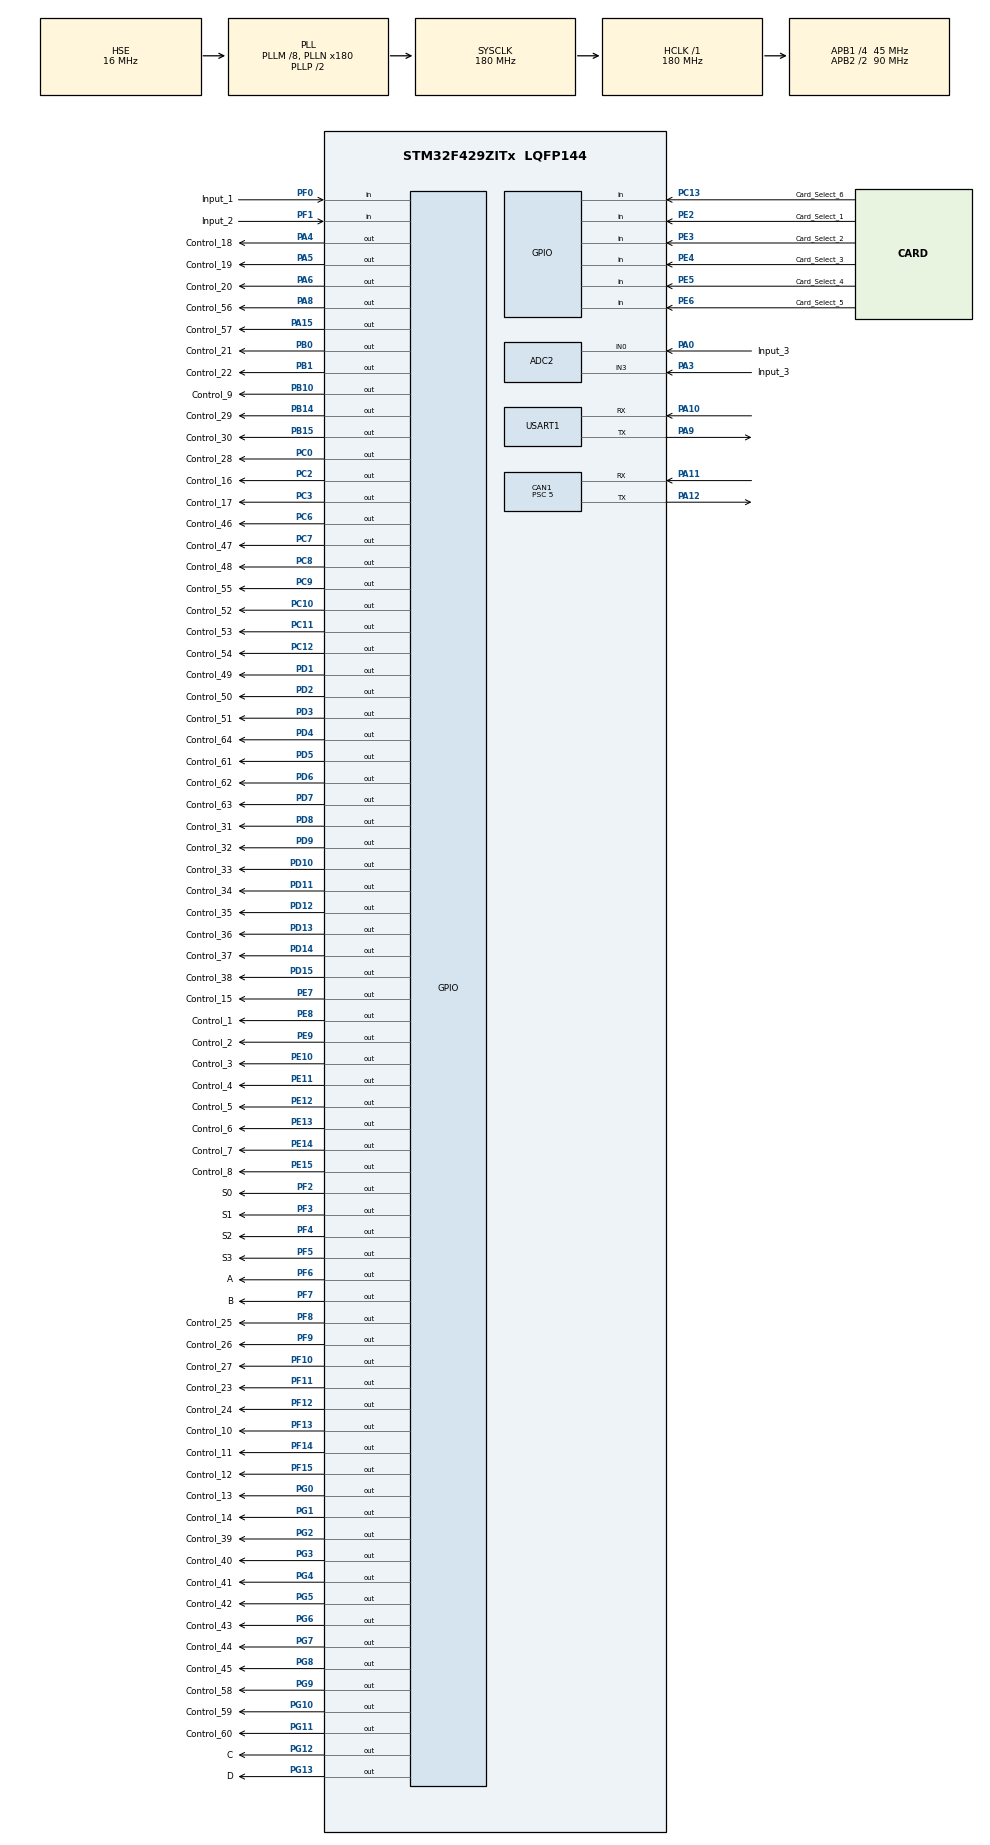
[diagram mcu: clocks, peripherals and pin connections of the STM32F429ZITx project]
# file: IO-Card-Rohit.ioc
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ADC2.Channel-0\#ChannelRegularConversion=ADC_CHANNEL_0
ADC2.Channel-1\#ChannelRegularConversion=ADC_CHANNEL_0
ADC2.ClockPrescaler=ADC_CLOCK_SYNC_PCLK_DIV4
ADC2.ContinuousConvMode=ENABLE
ADC2.NbrOfConversion=2
ADC2.NbrOfConversionFlag=1
ADC2.Rank-0\#ChannelRegularConversion=1
ADC2.Rank-1\#ChannelRegularConversion=2
ADC2.SamplingTime-0\#ChannelRegularConversion=ADC_SAMPLETIME_3CYCLES
ADC2.SamplingTime-1\#ChannelRegularConversion=ADC_SAMPLETIME_3CYCLES
ADC2.ScanConvMode=ENABLE
CAN1.BS1=CAN_BS1_6TQ
CAN1.BS2=CAN_BS2_2TQ
CAN1.CalculateBaudRate=1000000
CAN1.CalculateTimeBit=1000
CAN1.CalculateTimeQuantum=111.11111111111111
CAN1.Prescaler=5
Mcu.Family=STM32F4
Mcu.Name=STM32F429ZITx
Mcu.Package=LQFP144
NVIC.ADC_IRQn=true\:2\:0\:true\:false\:true\:true\:true\:true
NVIC.CAN1_RX0_IRQn=true\:0\:0\:false\:false\:true\:true\:true\:true
NVIC.PriorityGroup=NVIC_PRIORITYGROUP_4
NVIC.TIM1_UP_TIM10_IRQn=true\:0\:0\:true\:false\:true\:false\:true\:true
NVIC.TimeBase=TIM1_UP_TIM10_IRQn
NVIC.TimeBaseIP=TIM1
NVIC.USART1_IRQn=true\:0\:0\:false\:false\:true\:true\:true\:true
PA0/WKUP.GPIO_Label=Input_3
PA0/WKUP.Signal=ADCx_IN0
PA10.Mode=Asynchronous
PA10.Signal=USART1_RX
PA11.Mode=CAN_Activate
PA11.Signal=CAN1_RX
PA12.Mode=CAN_Activate
PA12.Signal=CAN1_TX
PA13.Mode=Serial_Wire
PA13.Signal=SYS_JTMS-SWDIO
PA14.Mode=Serial_Wire
PA14.Signal=SYS_JTCK-SWCLK
PA15.GPIO_Label=Control_57
PA15.GPIO_PuPd=GPIO_PULLDOWN
PA15.GPIO_Speed=GPIO_SPEED_FREQ_MEDIUM
PA15.Signal=GPIO_Output
PA3.GPIO_Label=Input_3
PA3.Signal=ADCx_IN3
PA4.GPIO_Label=Control_18
PA4.GPIO_PuPd=GPIO_PULLDOWN
PA4.GPIO_Speed=GPIO_SPEED_FREQ_MEDIUM
PA4.Signal=GPIO_Output
PA5.GPIO_Label=Control_19
PA5.GPIO_PuPd=GPIO_PULLDOWN
PA5.GPIO_Speed=GPIO_SPEED_FREQ_MEDIUM
PA5.Signal=GPIO_Output
PA6.GPIO_Label=Control_20
PA6.GPIO_PuPd=GPIO_PULLDOWN
PA6.GPIO_Speed=GPIO_SPEED_FREQ_MEDIUM
PA6.Signal=GPIO_Output
PA8.GPIO_Label=Control_56
PA8.GPIO_PuPd=GPIO_PULLDOWN
PA8.GPIO_Speed=GPIO_SPEED_FREQ_MEDIUM
PA8.Signal=GPIO_Output
PA9.Mode=Asynchronous
PA9.Signal=USART1_TX
PB0.GPIO_Label=Control_21
PB0.GPIO_PuPd=GPIO_PULLDOWN
PB0.GPIO_Speed=GPIO_SPEED_FREQ_MEDIUM
PB0.Signal=GPIO_Output
PB1.GPIO_Label=Control_22
PB1.GPIO_PuPd=GPIO_PULLDOWN
PB1.GPIO_Speed=GPIO_SPEED_FREQ_MEDIUM
PB1.Signal=GPIO_Output
PB10.GPIO_Label=Control_9
PB10.GPIO_PuPd=GPIO_PULLDOWN
PB10.GPIO_Speed=GPIO_SPEED_FREQ_MEDIUM
PB10.Signal=GPIO_Output
PB14.GPIO_Label=Control_29
PB14.GPIO_PuPd=GPIO_PULLDOWN
PB14.GPIO_Speed=GPIO_SPEED_FREQ_MEDIUM
PB14.Signal=GPIO_Output
PB15.GPIO_Label=Control_30
PB15.GPIO_PuPd=GPIO_PULLDOWN
PB15.GPIO_Speed=GPIO_SPEED_FREQ_MEDIUM
PB15.Signal=GPIO_Output
PC0.GPIO_Label=Control_28
PC0.GPIO_PuPd=GPIO_PULLDOWN
PC0.GPIO_Speed=GPIO_SPEED_FREQ_MEDIUM
PC0.Signal=GPIO_Output
PC10.GPIO_Label=Control_52
PC10.GPIO_PuPd=GPIO_PULLDOWN
PC10.GPIO_Speed=GPIO_SPEED_FREQ_MEDIUM
PC10.Signal=GPIO_Output
PC11.GPIO_Label=Control_53
PC11.GPIO_PuPd=GPIO_PULLDOWN
PC11.GPIO_Speed=GPIO_SPEED_FREQ_MEDIUM
PC11.Signal=GPIO_Output
PC12.GPIO_Label=Control_54
PC12.GPIO_PuPd=GPIO_PULLDOWN
PC12.GPIO_Speed=GPIO_SPEED_FREQ_MEDIUM
PC12.Signal=GPIO_Output
PC13.GPIO_Label=Card_Select_6
PC13.GPIO_Mode=GPIO_MODE_INPUT
PC13.GPIO_PuPd=GPIO_PULLUP
PC13.Signal=GPIO_Input
PC2.GPIO_Label=Control_16
PC2.GPIO_PuPd=GPIO_PULLDOWN
PC2.GPIO_Speed=GPIO_SPEED_FREQ_MEDIUM
PC2.Signal=GPIO_Output
PC3.GPIO_Label=Control_17
PC3.GPIO_PuPd=GPIO_PULLDOWN
PC3.GPIO_Speed=GPIO_SPEED_FREQ_MEDIUM
PC3.Signal=GPIO_Output
PC6.GPIO_Label=Control_46
PC6.GPIO_PuPd=GPIO_PULLDOWN
PC6.GPIO_Speed=GPIO_SPEED_FREQ_MEDIUM
PC6.Signal=GPIO_Output
PC7.GPIO_Label=Control_47
PC7.GPIO_PuPd=GPIO_PULLDOWN
PC7.GPIO_Speed=GPIO_SPEED_FREQ_MEDIUM
PC7.Signal=GPIO_Output
PC8.GPIO_Label=Control_48
PC8.GPIO_PuPd=GPIO_PULLDOWN
PC8.GPIO_Speed=GPIO_SPEED_FREQ_MEDIUM
PC8.Signal=GPIO_Output
PC9.GPIO_Label=Control_55
PC9.GPIO_PuPd=GPIO_PULLDOWN
PC9.GPIO_Speed=GPIO_SPEED_FREQ_MEDIUM
PC9.Signal=GPIO_Output
PD1.GPIO_Label=Control_49
PD1.GPIO_PuPd=GPIO_PULLDOWN
PD1.GPIO_Speed=GPIO_SPEED_FREQ_MEDIUM
PD1.Signal=GPIO_Output
PD10.GPIO_Label=Control_33
PD10.GPIO_PuPd=GPIO_PULLDOWN
PD10.GPIO_Speed=GPIO_SPEED_FREQ_MEDIUM
PD10.Signal=GPIO_Output
PD11.GPIO_Label=Control_34
PD11.GPIO_PuPd=GPIO_PULLDOWN
PD11.GPIO_Speed=GPIO_SPEED_FREQ_MEDIUM
PD11.Signal=GPIO_Output
PD12.GPIO_Label=Control_35
PD12.GPIO_PuPd=GPIO_PULLDOWN
PD12.GPIO_Speed=GPIO_SPEED_FREQ_MEDIUM
PD12.Signal=GPIO_Output
PD13.GPIO_Label=Control_36
PD13.GPIO_PuPd=GPIO_PULLDOWN
PD13.GPIO_Speed=GPIO_SPEED_FREQ_MEDIUM
PD13.Signal=GPIO_Output
PD14.GPIO_Label=Control_37
PD14.GPIO_PuPd=GPIO_PULLDOWN
PD14.GPIO_Speed=GPIO_SPEED_FREQ_MEDIUM
PD14.Signal=GPIO_Output
PD15.GPIO_Label=Control_38
PD15.GPIO_PuPd=GPIO_PULLDOWN
PD15.GPIO_Speed=GPIO_SPEED_FREQ_MEDIUM
PD15.Signal=GPIO_Output
PD2.GPIO_Label=Control_50
PD2.GPIO_PuPd=GPIO_PULLDOWN
PD2.GPIO_Speed=GPIO_SPEED_FREQ_MEDIUM
PD2.Signal=GPIO_Output
PD3.GPIO_Label=Control_51
PD3.GPIO_PuPd=GPIO_PULLDOWN
PD3.GPIO_Speed=GPIO_SPEED_FREQ_MEDIUM
PD3.Signal=GPIO_Output
PD4.GPIO_Label=Control_64
PD4.GPIO_PuPd=GPIO_PULLDOWN
PD4.GPIO_Speed=GPIO_SPEED_FREQ_MEDIUM
PD4.Signal=GPIO_Output
PD5.GPIO_Label=Control_61
PD5.GPIO_PuPd=GPIO_PULLDOWN
PD5.GPIO_Speed=GPIO_SPEED_FREQ_MEDIUM
PD5.Signal=GPIO_Output
PD6.GPIO_Label=Control_62
PD6.GPIO_PuPd=GPIO_PULLDOWN
PD6.GPIO_Speed=GPIO_SPEED_FREQ_MEDIUM
PD6.Signal=GPIO_Output
PD7.GPIO_Label=Control_63
PD7.GPIO_PuPd=GPIO_PULLDOWN
PD7.GPIO_Speed=GPIO_SPEED_FREQ_MEDIUM
PD7.Signal=GPIO_Output
PD8.GPIO_Label=Control_31
PD8.GPIO_PuPd=GPIO_PULLDOWN
PD8.GPIO_Speed=GPIO_SPEED_FREQ_MEDIUM
PD8.Signal=GPIO_Output
PD9.GPIO_Label=Control_32
PD9.GPIO_PuPd=GPIO_PULLDOWN
PD9.GPIO_Speed=GPIO_SPEED_FREQ_MEDIUM
PD9.Signal=GPIO_Output
PE10.GPIO_Label=Control_3
PE10.GPIO_PuPd=GPIO_PULLDOWN
PE10.GPIO_Speed=GPIO_SPEED_FREQ_MEDIUM
PE10.Signal=GPIO_Output
PE11.GPIO_Label=Control_4
PE11.GPIO_PuPd=GPIO_PULLDOWN
PE11.GPIO_Speed=GPIO_SPEED_FREQ_MEDIUM
PE11.Signal=GPIO_Output
PE12.GPIO_Label=Control_5
PE12.GPIO_PuPd=GPIO_PULLDOWN
PE12.GPIO_Speed=GPIO_SPEED_FREQ_MEDIUM
PE12.Signal=GPIO_Output
PE13.GPIO_Label=Control_6
PE13.GPIO_PuPd=GPIO_PULLDOWN
PE13.GPIO_Speed=GPIO_SPEED_FREQ_MEDIUM
PE13.Signal=GPIO_Output
PE14.GPIO_Label=Control_7
PE14.GPIO_PuPd=GPIO_PULLDOWN
PE14.GPIO_Speed=GPIO_SPEED_FREQ_MEDIUM
PE14.Signal=GPIO_Output
PE15.GPIO_Label=Control_8
PE15.GPIO_PuPd=GPIO_PULLDOWN
PE15.GPIO_Speed=GPIO_SPEED_FREQ_MEDIUM
PE15.Signal=GPIO_Output
PE2.GPIO_Label=Card_Select_1
PE2.GPIO_Mode=GPIO_MODE_INPUT
PE2.GPIO_PuPd=GPIO_PULLUP
PE2.Signal=GPIO_Input
PE3.GPIO_Label=Card_Select_2
PE3.GPIO_Mode=GPIO_MODE_INPUT
PE3.GPIO_PuPd=GPIO_PULLUP
PE3.Signal=GPIO_Input
PE4.GPIO_Label=Card_Select_3
PE4.GPIO_Mode=GPIO_MODE_INPUT
PE4.GPIO_PuPd=GPIO_PULLUP
PE4.Signal=GPIO_Input
PE5.GPIO_Label=Card_Select_4
PE5.GPIO_Mode=GPIO_MODE_INPUT
PE5.GPIO_PuPd=GPIO_PULLUP
PE5.Signal=GPIO_Input
PE6.GPIO_Label=Card_Select_5
PE6.GPIO_Mode=GPIO_MODE_INPUT
PE6.GPIO_PuPd=GPIO_PULLUP
PE6.Signal=GPIO_Input
PE7.GPIO_Label=Control_15
PE7.GPIO_PuPd=GPIO_PULLDOWN
PE7.GPIO_Speed=GPIO_SPEED_FREQ_MEDIUM
PE7.Signal=GPIO_Output
PE8.GPIO_Label=Control_1
PE8.GPIO_PuPd=GPIO_PULLDOWN
PE8.GPIO_Speed=GPIO_SPEED_FREQ_MEDIUM
PE8.Signal=GPIO_Output
PE9.GPIO_Label=Control_2
PE9.GPIO_PuPd=GPIO_PULLDOWN
PE9.GPIO_Speed=GPIO_SPEED_FREQ_MEDIUM
PE9.Signal=GPIO_Output
PF0.GPIO_Label=Input_1
PF0.Signal=GPIO_Input
PF1.GPIO_Label=Input_2
PF1.Signal=GPIO_Input
PF10.GPIO_Label=Control_27
PF10.GPIO_PuPd=GPIO_NOPULL
PF10.GPIO_Speed=GPIO_SPEED_FREQ_MEDIUM
PF10.Signal=GPIO_Output
PF11.GPIO_Label=Control_23
PF11.GPIO_PuPd=GPIO_NOPULL
PF11.GPIO_Speed=GPIO_SPEED_FREQ_MEDIUM
PF11.Signal=GPIO_Output
PF12.GPIO_Label=Control_24
PF12.GPIO_PuPd=GPIO_NOPULL
PF12.GPIO_Speed=GPIO_SPEED_FREQ_MEDIUM
PF12.Signal=GPIO_Output
PF13.GPIO_Label=Control_10
PF13.GPIO_PuPd=GPIO_NOPULL
PF13.GPIO_Speed=GPIO_SPEED_FREQ_MEDIUM
PF13.Signal=GPIO_Output
PF14.GPIO_Label=Control_11
PF14.GPIO_PuPd=GPIO_NOPULL
PF14.GPIO_Speed=GPIO_SPEED_FREQ_MEDIUM
PF14.Signal=GPIO_Output
PF15.GPIO_Label=Control_12
PF15.GPIO_PuPd=GPIO_NOPULL
PF15.GPIO_Speed=GPIO_SPEED_FREQ_MEDIUM
PF15.Signal=GPIO_Output
PF2.GPIO_Label=S0
PF2.GPIO_PuPd=GPIO_NOPULL
PF2.GPIO_Speed=GPIO_SPEED_FREQ_MEDIUM
PF2.Signal=GPIO_Output
PF3.GPIO_Label=S1
PF3.GPIO_PuPd=GPIO_NOPULL
PF3.GPIO_Speed=GPIO_SPEED_FREQ_MEDIUM
PF3.Signal=GPIO_Output
PF4.GPIO_Label=S2
PF4.GPIO_PuPd=GPIO_NOPULL
PF4.GPIO_Speed=GPIO_SPEED_FREQ_MEDIUM
PF4.Signal=GPIO_Output
PF5.GPIO_Label=S3
PF5.GPIO_PuPd=GPIO_NOPULL
PF5.GPIO_Speed=GPIO_SPEED_FREQ_MEDIUM
PF5.Signal=GPIO_Output
PF6.GPIO_Label=A
PF6.GPIO_PuPd=GPIO_NOPULL
PF6.GPIO_Speed=GPIO_SPEED_FREQ_MEDIUM
PF6.Signal=GPIO_Output
PF7.GPIO_Label=B
PF7.GPIO_PuPd=GPIO_NOPULL
PF7.GPIO_Speed=GPIO_SPEED_FREQ_MEDIUM
PF7.Signal=GPIO_Output
PF8.GPIO_Label=Control_25
PF8.GPIO_PuPd=GPIO_NOPULL
PF8.GPIO_Speed=GPIO_SPEED_FREQ_MEDIUM
PF8.Signal=GPIO_Output
PF9.GPIO_Label=Control_26
PF9.GPIO_PuPd=GPIO_NOPULL
PF9.GPIO_Speed=GPIO_SPEED_FREQ_MEDIUM
PF9.Signal=GPIO_Output
PG0.GPIO_Label=Control_13
PG0.GPIO_PuPd=GPIO_PULLDOWN
PG0.GPIO_Speed=GPIO_SPEED_FREQ_MEDIUM
PG0.Signal=GPIO_Output
PG1.GPIO_Label=Control_14
PG1.GPIO_PuPd=GPIO_PULLDOWN
PG1.GPIO_Speed=GPIO_SPEED_FREQ_MEDIUM
PG1.Signal=GPIO_Output
PG10.GPIO_Label=Control_59
PG10.GPIO_PuPd=GPIO_PULLDOWN
PG10.GPIO_Speed=GPIO_SPEED_FREQ_MEDIUM
PG10.Signal=GPIO_Output
PG11.GPIO_Label=Control_60
PG11.GPIO_PuPd=GPIO_PULLDOWN
PG11.GPIO_Speed=GPIO_SPEED_FREQ_MEDIUM
PG11.Signal=GPIO_Output
PG12.GPIO_Label=C
PG12.GPIO_PuPd=GPIO_PULLDOWN
PG12.GPIO_Speed=GPIO_SPEED_FREQ_MEDIUM
PG12.Signal=GPIO_Output
PG13.GPIO_Label=D
PG13.GPIO_PuPd=GPIO_PULLDOWN
PG13.GPIO_Speed=GPIO_SPEED_FREQ_MEDIUM
PG13.Signal=GPIO_Output
PG2.GPIO_Label=Control_39
PG2.GPIO_PuPd=GPIO_PULLDOWN
PG2.GPIO_Speed=GPIO_SPEED_FREQ_MEDIUM
PG2.Signal=GPIO_Output
PG3.GPIO_Label=Control_40
PG3.GPIO_PuPd=GPIO_PULLDOWN
PG3.GPIO_Speed=GPIO_SPEED_FREQ_MEDIUM
PG3.Signal=GPIO_Output
PG4.GPIO_Label=Control_41
PG4.GPIO_PuPd=GPIO_PULLDOWN
PG4.GPIO_Speed=GPIO_SPEED_FREQ_MEDIUM
PG4.Signal=GPIO_Output
PG5.GPIO_Label=Control_42
PG5.GPIO_PuPd=GPIO_PULLDOWN
PG5.GPIO_Speed=GPIO_SPEED_FREQ_MEDIUM
PG5.Signal=GPIO_Output
PG6.GPIO_Label=Control_43
PG6.GPIO_PuPd=GPIO_PULLDOWN
PG6.GPIO_Speed=GPIO_SPEED_FREQ_MEDIUM
PG6.Signal=GPIO_Output
PG7.GPIO_Label=Control_44
PG7.GPIO_PuPd=GPIO_PULLDOWN
PG7.GPIO_Speed=GPIO_SPEED_FREQ_MEDIUM
PG7.Signal=GPIO_Output
PG8.GPIO_Label=Control_45
PG8.GPIO_PuPd=GPIO_PULLDOWN
PG8.GPIO_Speed=GPIO_SPEED_FREQ_MEDIUM
PG8.Signal=GPIO_Output
PG9.GPIO_Label=Control_58
PG9.GPIO_PuPd=GPIO_PULLDOWN
PG9.GPIO_Speed=GPIO_SPEED_FREQ_MEDIUM
PG9.Signal=GPIO_Output
PH0/OSC_IN.Mode=HSE-External-Oscillator
PH0/OSC_IN.Signal=RCC_OSC_IN
PH1/OSC_OUT.Mode=HSE-External-Oscillator
PH1/OSC_OUT.Signal=RCC_OSC_OUT
ProjectManager.HeapSize=0x200
ProjectManager.StackSize=0x400
ProjectManager.TargetToolchain=CMake
RCC.48MHZClocksFreq_Value=90000000
RCC.AHBFreq_Value=180000000
RCC.APB1CLKDivider=RCC_HCLK_DIV4
RCC.APB1Freq_Value=45000000
RCC.APB1TimFreq_Value=90000000
RCC.APB2CLKDivider=RCC_HCLK_DIV2
RCC.APB2Freq_Value=90000000
RCC.APB2TimFreq_Value=180000000
RCC.CortexFreq_Value=180000000
RCC.HCLKFreq_Value=180000000
RCC.HSE_VALUE=16000000
RCC.HSI_VALUE=16000000
RCC.LSE_VALUE=32768
RCC.PLLM=8
RCC.PLLN=180
RCC.PLLSourceVirtual=RCC_PLLSOURCE_HSE
RCC.PWREXT_OverDrive=PWREXT_OverDrive_ACTIVATED
RCC.PWR_Regulator_Voltage_Scale=PWR_REGULATOR_VOLTAGE_SCALE1
RCC.SYSCLKFreq_VALUE=180000000
RCC.SYSCLKSource=RCC_SYSCLKSOURCE_PLLCLK
RCC.VCOOutputFreq_Value=360000000
SH.ADCx_IN0.0=ADC2_IN0,IN0
SH.ADCx_IN3.0=ADC2_IN3,IN3
USART1.VirtualMode=VM_ASYNC
VP_SYS_VS_tim1.Mode=TIM1
board=custom

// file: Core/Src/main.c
/* USER CODE BEGIN Header */
/**
  ******************************************************************************
  * @file           : main.c
  * @brief          : Main program body
  * Created on      : 23-Mar-2026
  * Author          : Rohit Jadhav
  * Hex Version     : IO-Card-V1.3.hex (1Mbps)
  ******************************************************************************
  * @attention
  *
  * Copyright (c) 2026 STMicroelectronics.
  * All rights reserved.
  *
  * This software is licensed under terms that can be found in the LICENSE file
  * in the root directory of this software component.
  * If no LICENSE file comes with this software, it is provided AS-IS.
  *
  ******************************************************************************
  */
/* USER CODE END Header */
#include "main.h"
#include "engine.h"
#include "operations.h"

ADC_HandleTypeDef hadc2;

CAN_HandleTypeDef hcan1;

UART_HandleTypeDef huart1;

/* USER CODE BEGIN PV */
CAN_RxHeaderTypeDef rxHeader; //CAN Bus Transmit Header
CAN_TxHeaderTypeDef txHeader; //CAN Bus Receive Header
uint8_t canRX[8] = {0,0,0,0,0,0,0,0};  //CAN Bus Receive Buffer
CAN_FilterTypeDef canfil; //CAN Bus Filter
uint32_t canMailbox; //CAN Bus Mail box variable

unsigned char Card[4]={0x04,0x00,0x00,0x00};
int receive_flag; // detection of received message on CAN
unsigned int operation,pin_no,pin_dir,pin_status; //Detection of operation
/* USER CODE END PV */

void SystemClock_Config(void);
static void MX_GPIO_Init(void);
static void MX_ADC2_Init(void);
static void MX_CAN1_Init(void);
static void MX_USART1_UART_Init(void);

/* USER CODE BEGIN 0 */
void ADC_ch0()
{
	ADC_ChannelConfTypeDef sConfig = {0};
	sConfig.Channel = ADC_CHANNEL_0;
  sConfig.Rank = 1;
  sConfig.SamplingTime = ADC_SAMPLETIME_480CYCLES;
  if (HAL_ADC_ConfigChannel(&hadc2, &sConfig) != HAL_OK)
  {
    Error_Handler();
  }
}
void ADC_ch3()
{
	ADC_ChannelConfTypeDef sConfig = {0};
	sConfig.Channel = ADC_CHANNEL_3;
  sConfig.Rank = 1;
  sConfig.SamplingTime = ADC_SAMPLETIME_480CYCLES;
  if (HAL_ADC_ConfigChannel(&hadc2, &sConfig) != HAL_OK)
  {
    Error_Handler();
  }
}
/* USER CODE END 0 */

int main(void)
{

  /* MCU Configuration--------------------------------------------------------*/

  /* Reset of all peripherals, Initializes the Flash interface and the Systick. */
  HAL_Init();

  /* Configure the system clock */
  SystemClock_Config();

  /* Initialize all configured peripherals */
  MX_GPIO_Init();
  HAL_Delay(500);
  MX_ADC2_Init();
  MX_CAN1_Init();
  MX_USART1_UART_Init();
  /* USER CODE BEGIN 2 */
  card_status();

  canfil.FilterBank = 0;
	canfil.FilterMode = CAN_FILTERMODE_IDMASK;
	canfil.FilterFIFOAssignment = CAN_RX_FIFO0;
	canfil.FilterIdHigh =(0x7D0 + Card[3]) <<5;
	canfil.FilterIdLow = 0;
	canfil.FilterMaskIdHigh = 0xffff;
	canfil.FilterMaskIdLow = 0;
	canfil.FilterScale = CAN_FILTERSCALE_32BIT;
	canfil.FilterActivation = ENABLE;
	canfil.SlaveStartFilterBank = 14;

	txHeader.DLC = 8;
	txHeader.IDE = CAN_ID_STD;
	txHeader.RTR = CAN_RTR_DATA;
	txHeader.StdId =0x200 + Card[3]; //0X030; //fixed ID for OS to receive//variable ID for OS to receive 0x200 + Card[3] is used to send the message to OS as per the card number. For example, if card number is 4, then the ID will be 0x204. This allows OS to identify which card has sent the message.
	txHeader.ExtId = 0x02;
	txHeader.TransmitGlobalTime = DISABLE;

	HAL_CAN_ConfigFilter(&hcan1,&canfil);
	if(HAL_CAN_Start(&hcan1)==HAL_OK)
	{
		HAL_CAN_ActivateNotification(&hcan1,CAN_IT_RX_FIFO0_MSG_PENDING);
	}
	else
	{
		HAL_CAN_Stop(&hcan1);
		HAL_Delay(100);
		HAL_CAN_Start(&hcan1);
    HAL_CAN_ActivateNotification(&hcan1,CAN_IT_RX_FIFO0_MSG_PENDING);
	}

	HAL_GPIO_WritePin(GPIOG, D_Pin, 0);
	HAL_GPIO_WritePin(GPIOG, C_Pin, 0);
  /* USER CODE END 2 */

  /* Infinite loop */
  while (1)
  {
    if(receive_flag==1)
				{
					switch(operation)
					{
					case 1:
						HAL_GPIO_WritePin(GPIOG, C_Pin, 0);//changed to C_Pin from GPIO_PIN_12
		        HAL_GPIO_WritePin(GPIOG, D_Pin, 0);//changed to D_Pin from GPIO_PIN_13
						single_read();
						break;
					case 2:
						HAL_GPIO_WritePin(GPIOG, C_Pin, 0);
		        HAL_GPIO_WritePin(GPIOG, D_Pin, 0);
						single_write();
						break;
					case 3:
						HAL_GPIO_WritePin(GPIOG, C_Pin, 0);
		        HAL_GPIO_WritePin(GPIOG, D_Pin, 0);
						multiple_read();
						break;
					case 4:
						HAL_GPIO_WritePin(GPIOG, C_Pin, 0);
		        HAL_GPIO_WritePin(GPIOG, D_Pin, 0);
						card_status();
						break;
					case 5:
						HAL_GPIO_WritePin(GPIOG, C_Pin, 0);
		        HAL_GPIO_WritePin(GPIOG, D_Pin, 0);
						reinit();
						break;
					case 6:
					  HAL_GPIO_WritePin(GPIOG, C_Pin, 1);
		        HAL_GPIO_WritePin(GPIOG, D_Pin, 1);
						analog_read();
						break;
					}
					receive_flag = 0;
				}
  }
}

void SystemClock_Config(void)
{
  RCC_OscInitTypeDef RCC_OscInitStruct = {0};
  RCC_ClkInitTypeDef RCC_ClkInitStruct = {0};

  /** Configure the main internal regulator output voltage
  */
  __HAL_RCC_PWR_CLK_ENABLE();
  __HAL_PWR_VOLTAGESCALING_CONFIG(PWR_REGULATOR_VOLTAGE_SCALE1);

  /** Initializes the RCC Oscillators according to the specified parameters
  * in the RCC_OscInitTypeDef structure.
  */
  RCC_OscInitStruct.OscillatorType = RCC_OSCILLATORTYPE_HSE;
  RCC_OscInitStruct.HSEState = RCC_HSE_ON;
  RCC_OscInitStruct.PLL.PLLState = RCC_PLL_ON;
  RCC_OscInitStruct.PLL.PLLSource = RCC_PLLSOURCE_HSE;
  RCC_OscInitStruct.PLL.PLLM = 8;
  RCC_OscInitStruct.PLL.PLLN = 180;
  RCC_OscInitStruct.PLL.PLLP = RCC_PLLP_DIV2;
  RCC_OscInitStruct.PLL.PLLQ = 4;
  if (HAL_RCC_OscConfig(&RCC_OscInitStruct) != HAL_OK)
  {
    Error_Handler();
  }

  /** Activate the Over-Drive mode
  */
  if (HAL_PWREx_EnableOverDrive() != HAL_OK)
  {
    Error_Handler();
  }

  /** Initializes the CPU, AHB and APB buses clocks
  */
  RCC_ClkInitStruct.ClockType = RCC_CLOCKTYPE_HCLK|RCC_CLOCKTYPE_SYSCLK
                              |RCC_CLOCKTYPE_PCLK1|RCC_CLOCKTYPE_PCLK2;
  RCC_ClkInitStruct.SYSCLKSource = RCC_SYSCLKSOURCE_PLLCLK;
  RCC_ClkInitStruct.AHBCLKDivider = RCC_SYSCLK_DIV1;
  RCC_ClkInitStruct.APB1CLKDivider = RCC_HCLK_DIV4;
  RCC_ClkInitStruct.APB2CLKDivider = RCC_HCLK_DIV2;

  if (HAL_RCC_ClockConfig(&RCC_ClkInitStruct, FLASH_LATENCY_5) != HAL_OK)
  {
    Error_Handler();
  }
}

static void MX_ADC2_Init(void)
{

  ADC_ChannelConfTypeDef sConfig = {0};

  /** Configure the global features of the ADC (Clock, Resolution, Data Alignment and number of conversion)
  */
  hadc2.Instance = ADC2;
  hadc2.Init.ClockPrescaler = ADC_CLOCK_SYNC_PCLK_DIV4;
  hadc2.Init.Resolution = ADC_RESOLUTION_12B;
  hadc2.Init.ScanConvMode = ENABLE;
  hadc2.Init.ContinuousConvMode = ENABLE;
  hadc2.Init.DiscontinuousConvMode = DISABLE;
  hadc2.Init.ExternalTrigConvEdge = ADC_EXTERNALTRIGCONVEDGE_NONE;
  hadc2.Init.ExternalTrigConv = ADC_SOFTWARE_START;
  hadc2.Init.DataAlign = ADC_DATAALIGN_RIGHT;
  hadc2.Init.NbrOfConversion = 2;
  hadc2.Init.DMAContinuousRequests = DISABLE;
  hadc2.Init.EOCSelection = ADC_EOC_SINGLE_CONV;
  if (HAL_ADC_Init(&hadc2) != HAL_OK)
  {
    Error_Handler();
  }

  /** Configure for the selected ADC regular channel its corresponding rank in the sequencer and its sample time.
  */
  sConfig.Channel = ADC_CHANNEL_0;
  sConfig.Rank = 1;
  sConfig.SamplingTime = ADC_SAMPLETIME_15CYCLES;
  if (HAL_ADC_ConfigChannel(&hadc2, &sConfig) != HAL_OK)
  {
    Error_Handler();
  }

  /** Configure for the selected ADC regular channel its corresponding rank in the sequencer and its sample time.
  */
  sConfig.Channel = ADC_CHANNEL_3;
  sConfig.Rank = 2;
  if (HAL_ADC_ConfigChannel(&hadc2, &sConfig) != HAL_OK)
  {
    Error_Handler();
  }

}

static void MX_CAN1_Init(void)
{

  hcan1.Instance = CAN1;
  hcan1.Init.Prescaler = 5;
  hcan1.Init.Mode = CAN_MODE_NORMAL;
  hcan1.Init.SyncJumpWidth = CAN_SJW_1TQ;
  hcan1.Init.TimeSeg1 = CAN_BS1_6TQ;
  hcan1.Init.TimeSeg2 = CAN_BS2_2TQ;
  hcan1.Init.TimeTriggeredMode = DISABLE;
  hcan1.Init.AutoBusOff = DISABLE;
  hcan1.Init.AutoWakeUp = DISABLE;
  hcan1.Init.AutoRetransmission = DISABLE;
  hcan1.Init.ReceiveFifoLocked = DISABLE;
  hcan1.Init.TransmitFifoPriority = DISABLE;
  if (HAL_CAN_Init(&hcan1) != HAL_OK)
  {
    Error_Handler();
  }

}

static void MX_USART1_UART_Init(void)
{

  huart1.Instance = USART1;
  huart1.Init.BaudRate = 115200;
  huart1.Init.WordLength = UART_WORDLENGTH_8B;
  huart1.Init.StopBits = UART_STOPBITS_1;
  huart1.Init.Parity = UART_PARITY_NONE;
  huart1.Init.Mode = UART_MODE_TX_RX;
  huart1.Init.HwFlowCtl = UART_HWCONTROL_NONE;
  huart1.Init.OverSampling = UART_OVERSAMPLING_16;
  if (HAL_UART_Init(&huart1) != HAL_OK)
  {
    Error_Handler();
  }

}

static void MX_GPIO_Init(void)
{
  GPIO_InitTypeDef GPIO_InitStruct = {0};

  /* GPIO Ports Clock Enable */
  __HAL_RCC_GPIOE_CLK_ENABLE();
  __HAL_RCC_GPIOC_CLK_ENABLE();
  __HAL_RCC_GPIOF_CLK_ENABLE();
  __HAL_RCC_GPIOH_CLK_ENABLE();
  __HAL_RCC_GPIOA_CLK_ENABLE();
  __HAL_RCC_GPIOB_CLK_ENABLE();
  __HAL_RCC_GPIOG_CLK_ENABLE();
  __HAL_RCC_GPIOD_CLK_ENABLE();

  /*Configure GPIO pin Output Level */
  HAL_GPIO_WritePin(GPIOF, S0_Pin|S1_Pin|S2_Pin|S3_Pin
                          |A_Pin|B_Pin|Control_25_Pin|Control_26_Pin
                          |Control_27_Pin|Control_23_Pin|Control_24_Pin|Control_10_Pin
                          |Control_11_Pin|Control_12_Pin, GPIO_PIN_RESET);

  /*Configure GPIO pin Output Level */
  HAL_GPIO_WritePin(GPIOC, Control_28_Pin|Control_16_Pin|Control_17_Pin|Control_46_Pin
                          |Control_47_Pin|Control_48_Pin|Control_55_Pin|Control_52_Pin
                          |Control_53_Pin|Control_54_Pin, GPIO_PIN_RESET);

  /*Configure GPIO pin Output Level */
  HAL_GPIO_WritePin(GPIOA, Control_18_Pin|Control_19_Pin|Control_20_Pin|Control_56_Pin
                          |Control_57_Pin, GPIO_PIN_RESET);

  /*Configure GPIO pin Output Level */
  HAL_GPIO_WritePin(GPIOB, Control_21_Pin|Control_22_Pin|Control_9_Pin|Control_29_Pin
                          |Control_30_Pin, GPIO_PIN_RESET);

  /*Configure GPIO pin Output Level */
  HAL_GPIO_WritePin(GPIOG, Control_13_Pin|Control_14_Pin|Control_39_Pin|Control_40_Pin
                          |Control_41_Pin|Control_42_Pin|Control_43_Pin|Control_44_Pin
                          |Control_45_Pin|Control_58_Pin|Control_59_Pin|Control_60_Pin
                          |C_Pin|D_Pin, GPIO_PIN_RESET);

  /*Configure GPIO pin Output Level */
  HAL_GPIO_WritePin(GPIOE, Control_15_Pin|Control_1_Pin|Control_2_Pin|Control_3_Pin
                          |Control_4_Pin|Control_5_Pin|Control_6_Pin|Control_7_Pin
                          |Control_8_Pin, GPIO_PIN_RESET);

  /*Configure GPIO pin Output Level */
  HAL_GPIO_WritePin(GPIOD, Control_31_Pin|Control_32_Pin|Control_33_Pin|Control_34_Pin
                          |Control_35_Pin|Control_36_Pin|Control_37_Pin|Control_38_Pin
                          |Control_49_Pin|Control_50_Pin|Control_51_Pin|Control_64_Pin
                          |Control_61_Pin|Control_62_Pin|Control_63_Pin, GPIO_PIN_RESET);

  /*Configure GPIO pins : Card_Select_1_Pin Card_Select_2_Pin Card_Select_3_Pin Card_Select_4_Pin
                           Card_Select_5_Pin */
  GPIO_InitStruct.Pin = Card_Select_1_Pin|Card_Select_2_Pin|Card_Select_3_Pin|Card_Select_4_Pin
                          |Card_Select_5_Pin;
  GPIO_InitStruct.Mode = GPIO_MODE_INPUT;
  GPIO_InitStruct.Pull = GPIO_PULLUP;
  HAL_GPIO_Init(GPIOE, &GPIO_InitStruct);

  /*Configure GPIO pin : Card_Select_6_Pin */
  GPIO_InitStruct.Pin = Card_Select_6_Pin;
  GPIO_InitStruct.Mode = GPIO_MODE_INPUT;
  GPIO_InitStruct.Pull = GPIO_PULLUP;
  HAL_GPIO_Init(Card_Select_6_GPIO_Port, &GPIO_InitStruct);

  /*Configure GPIO pins : Input_1_Pin Input_2_Pin */
  GPIO_InitStruct.Pin = Input_1_Pin|Input_2_Pin;
  GPIO_InitStruct.Mode = GPIO_MODE_INPUT;
  GPIO_InitStruct.Pull = GPIO_NOPULL;
  HAL_GPIO_Init(GPIOF, &GPIO_InitStruct);

  /*Configure GPIO pins : S0_Pin S1_Pin S2_Pin S3_Pin
                           A_Pin B_Pin Control_25_Pin Control_26_Pin
                           Control_27_Pin Control_23_Pin Control_24_Pin Control_10_Pin
                           Control_11_Pin Control_12_Pin */
  GPIO_InitStruct.Pin = S0_Pin|S1_Pin|S2_Pin|S3_Pin
                          |A_Pin|B_Pin|Control_25_Pin|Control_26_Pin
                          |Control_27_Pin|Control_23_Pin|Control_24_Pin|Control_10_Pin
                          |Control_11_Pin|Control_12_Pin;
  GPIO_InitStruct.Mode = GPIO_MODE_OUTPUT_PP;
  GPIO_InitStruct.Pull = GPIO_NOPULL;
  GPIO_InitStruct.Speed = GPIO_SPEED_FREQ_MEDIUM;
  HAL_GPIO_Init(GPIOF, &GPIO_InitStruct);

  /*Configure GPIO pins : Control_28_Pin Control_16_Pin Control_17_Pin Control_46_Pin
                           Control_47_Pin Control_48_Pin Control_55_Pin Control_52_Pin
                           Control_53_Pin Control_54_Pin */
  GPIO_InitStruct.Pin = Control_28_Pin|Control_16_Pin|Control_17_Pin|Control_46_Pin
                          |Control_47_Pin|Control_48_Pin|Control_55_Pin|Control_52_Pin
                          |Control_53_Pin|Control_54_Pin;
  GPIO_InitStruct.Mode = GPIO_MODE_OUTPUT_PP;
  GPIO_InitStruct.Pull = GPIO_PULLDOWN;
  GPIO_InitStruct.Speed = GPIO_SPEED_FREQ_MEDIUM;
  HAL_GPIO_Init(GPIOC, &GPIO_InitStruct);

  /*Configure GPIO pins : Control_18_Pin Control_19_Pin Control_20_Pin Control_56_Pin
                           Control_57_Pin */
  GPIO_InitStruct.Pin = Control_18_Pin|Control_19_Pin|Control_20_Pin|Control_56_Pin
                          |Control_57_Pin;
  GPIO_InitStruct.Mode = GPIO_MODE_OUTPUT_PP;
  GPIO_InitStruct.Pull = GPIO_PULLDOWN;
  GPIO_InitStruct.Speed = GPIO_SPEED_FREQ_MEDIUM;
  HAL_GPIO_Init(GPIOA, &GPIO_InitStruct);

  /*Configure GPIO pins : Control_21_Pin Control_22_Pin Control_9_Pin Control_29_Pin
                           Control_30_Pin */
  GPIO_InitStruct.Pin = Control_21_Pin|Control_22_Pin|Control_9_Pin|Control_29_Pin
                          |Control_30_Pin;
  GPIO_InitStruct.Mode = GPIO_MODE_OUTPUT_PP;
  GPIO_InitStruct.Pull = GPIO_PULLDOWN;
  GPIO_InitStruct.Speed = GPIO_SPEED_FREQ_MEDIUM;
  HAL_GPIO_Init(GPIOB, &GPIO_InitStruct);

  /*Configure GPIO pins : Control_13_Pin Control_14_Pin Control_39_Pin Control_40_Pin
                           Control_41_Pin Control_42_Pin Control_43_Pin Control_44_Pin
                           Control_45_Pin Control_58_Pin Control_59_Pin Control_60_Pin
                           C_Pin D_Pin */
  GPIO_InitStruct.Pin = Control_13_Pin|Control_14_Pin|Control_39_Pin|Control_40_Pin
                          |Control_41_Pin|Control_42_Pin|Control_43_Pin|Control_44_Pin
                          |Control_45_Pin|Control_58_Pin|Control_59_Pin|Control_60_Pin
                          |C_Pin|D_Pin;
  GPIO_InitStruct.Mode = GPIO_MODE_OUTPUT_PP;
  GPIO_InitStruct.Pull = GPIO_PULLDOWN;
  GPIO_InitStruct.Speed = GPIO_SPEED_FREQ_MEDIUM;
  HAL_GPIO_Init(GPIOG, &GPIO_InitStruct);

  /*Configure GPIO pins : Control_15_Pin Control_1_Pin Control_2_Pin Control_3_Pin
                           Control_4_Pin Control_5_Pin Control_6_Pin Control_7_Pin
                           Control_8_Pin */
  GPIO_InitStruct.Pin = Control_15_Pin|Control_1_Pin|Control_2_Pin|Control_3_Pin
                          |Control_4_Pin|Control_5_Pin|Control_6_Pin|Control_7_Pin
                          |Control_8_Pin;
  GPIO_InitStruct.Mode = GPIO_MODE_OUTPUT_PP;
  GPIO_InitStruct.Pull = GPIO_PULLDOWN;
  GPIO_InitStruct.Speed = GPIO_SPEED_FREQ_MEDIUM;
  HAL_GPIO_Init(GPIOE, &GPIO_InitStruct);

  /*Configure GPIO pins : Control_31_Pin Control_32_Pin Control_33_Pin Control_34_Pin
                           Control_35_Pin Control_36_Pin Control_37_Pin Control_38_Pin
                           Control_49_Pin Control_50_Pin Control_51_Pin Control_64_Pin
                           Control_61_Pin Control_62_Pin Control_63_Pin */
  GPIO_InitStruct.Pin = Control_31_Pin|Control_32_Pin|Control_33_Pin|Control_34_Pin
                          |Control_35_Pin|Control_36_Pin|Control_37_Pin|Control_38_Pin
                          |Control_49_Pin|Control_50_Pin|Control_51_Pin|Control_64_Pin
                          |Control_61_Pin|Control_62_Pin|Control_63_Pin;
  GPIO_InitStruct.Mode = GPIO_MODE_OUTPUT_PP;
  GPIO_InitStruct.Pull = GPIO_PULLDOWN;
  GPIO_InitStruct.Speed = GPIO_SPEED_FREQ_MEDIUM;
  HAL_GPIO_Init(GPIOD, &GPIO_InitStruct);

}

/* USER CODE BEGIN 4 */
void HAL_CAN_RxFifo0MsgPendingCallback(CAN_HandleTypeDef *hcan1)
{
    if(HAL_CAN_GetRxMessage(hcan1, CAN_RX_FIFO0, &rxHeader, canRX) == HAL_OK)
    {
        operation  = canRX[0];
        pin_no     = canRX[1];
        pin_dir    = canRX[2];
        pin_status = canRX[3];
        receive_flag = 1;
    }
    else
    {
        Error_Handler();
    }
}
/* USER CODE END 4 */

void HAL_TIM_PeriodElapsedCallback(TIM_HandleTypeDef *htim)
{
  if (htim->Instance == TIM1)
  {
    HAL_IncTick();
  }
}

void Error_Handler(void)
{
  /* USER CODE BEGIN Error_Handler_Debug */
  /* User can add his own implementation to report the HAL error return state */
  __disable_irq();
  while (1); //not calling HAL_CAN_IRQHandler(&hcan1); 24-Feb-26 Rohit
  /* USER CODE END Error_Handler_Debug */
}
